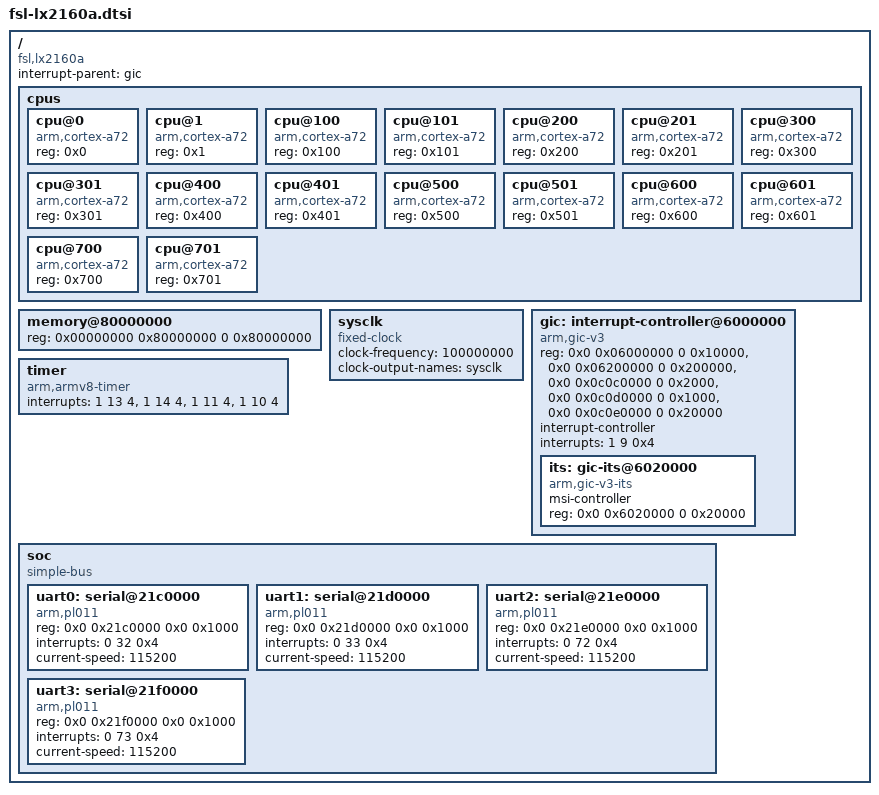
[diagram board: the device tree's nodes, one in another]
/*
 * Device Tree Include file for Layerscape-LX2160A family SoC.
 *
 * Copyright 2017 NXP
 *
 * Sriram Dash <sriram.dash@nxp.com>
 *
 * This file is dual-licensed: you can use it either under the terms
 * of the GPLv2 or the X11 license, at your option. Note that this dual
 * licensing only applies to this file, and not this project as a
 * whole.
 *
 *  a) This library is free software; you can redistribute it and/or
 *     modify it under the terms of the GNU General Public License as
 *     published by the Free Software Foundation; either version 2 of the
 *     License, or (at your option) any later version.
 *
 *     This library is distributed in the hope that it will be useful,
 *     but WITHOUT ANY WARRANTY; without even the implied warranty of
 *     MERCHANTABILITY or FITNESS FOR A PARTICULAR PURPOSE.  See the
 *     GNU General Public License for more details.
 *
 * Or, alternatively,
 *
 *  b) Permission is hereby granted, free of charge, to any person
 *     obtaining a copy of this software and associated documentation
 *     files (the "Software"), to deal in the Software without
 *     restriction, including without limitation the rights to use,
 *     copy, modify, merge, publish, distribute, sublicense, and/or
 *     sell copies of the Software, and to permit persons to whom the
 *     Software is furnished to do so, subject to the following
 *     conditions:
 *
 *     The above copyright notice and this permission notice shall be
 *     included in all copies or substantial portions of the Software.
 *
 *     THE SOFTWARE IS PROVIDED "AS IS", WITHOUT WARRANTY OF ANY KIND,
 *     EXPRESS OR IMPLIED, INCLUDING BUT NOT LIMITED TO THE WARRANTIES
 *     OF MERCHANTABILITY, FITNESS FOR A PARTICULAR PURPOSE AND
 *     NONINFRINGEMENT. IN NO EVENT SHALL THE AUTHORS OR COPYRIGHT
 *     HOLDERS BE LIABLE FOR ANY CLAIM, DAMAGES OR OTHER LIABILITY,
 *     WHETHER IN AN ACTION OF CONTRACT, TORT OR OTHERWISE, ARISING
 *     FROM, OUT OF OR IN CONNECTION WITH THE SOFTWARE OR THE USE OR
 *     OTHER DEALINGS IN THE SOFTWARE.
 */

#include <dt-bindings/interrupt-controller/arm-gic.h>

/memreserve/ 0x80000000 0x00010000;

/ {
	compatible = "fsl,lx2160a";
	interrupt-parent = <&gic>;
	#address-cells = <2>;
	#size-cells = <2>;

	cpus {
		#address-cells = <1>;
		#size-cells = <0>;

		/* We have 8 clusters having 2 Cortex-A72 cores each */
		cpu@0 {
			device_type = "cpu";
			compatible = "arm,cortex-a72";
			reg = <0x0>;
		};

		cpu@1 {
			device_type = "cpu";
			compatible = "arm,cortex-a72";
			reg = <0x1>;
		};

		cpu@100 {
			device_type = "cpu";
			compatible = "arm,cortex-a72";
			reg = <0x100>;
		};

		cpu@101 {
			device_type = "cpu";
			compatible = "arm,cortex-a72";
			reg = <0x101>;
		};

		cpu@200 {
			device_type = "cpu";
			compatible = "arm,cortex-a72";
			reg = <0x200>;
		};

		cpu@201 {
			device_type = "cpu";
			compatible = "arm,cortex-a72";
			reg = <0x201>;
		};

		cpu@300 {
			device_type = "cpu";
			compatible = "arm,cortex-a72";
			reg = <0x300>;
		};

		cpu@301 {
			device_type = "cpu";
			compatible = "arm,cortex-a72";
			reg = <0x301>;
		};

		cpu@400 {
			device_type = "cpu";
			compatible = "arm,cortex-a72";
			reg = <0x400>;
		};

		cpu@401 {
			device_type = "cpu";
			compatible = "arm,cortex-a72";
			reg = <0x401>;
		};

		cpu@500 {
			device_type = "cpu";
			compatible = "arm,cortex-a72";
			reg = <0x500>;
		};

		cpu@501 {
			device_type = "cpu";
			compatible = "arm,cortex-a72";
			reg = <0x501>;
		};

		cpu@600 {
			device_type = "cpu";
			compatible = "arm,cortex-a72";
			reg = <0x600>;
		};

		cpu@601 {
			device_type = "cpu";
			compatible = "arm,cortex-a72";
			reg = <0x601>;
		};

		cpu@700 {
			device_type = "cpu";
			compatible = "arm,cortex-a72";
			reg = <0x700>;
		};

		cpu@701 {
			device_type = "cpu";
			compatible = "arm,cortex-a72";
			reg = <0x701>;
		};

	};

	memory@80000000 {
		device_type = "memory";
		reg = <0x00000000 0x80000000 0 0x80000000>;
		      /* DRAM space - 1, size : 2 GB DRAM */
	};

	sysclk: sysclk {
		compatible = "fixed-clock";
		#clock-cells = <0>;
		clock-frequency = <100000000>;
		clock-output-names = "sysclk";
	};

	gic: interrupt-controller@6000000 {
		compatible = "arm,gic-v3";
		reg = <0x0 0x06000000 0 0x10000>, /* GIC Dist */
		      <0x0 0x06200000 0 0x200000>, /*GICR(RD_base + SGI_base)*/
		      <0x0 0x0c0c0000 0 0x2000>, /* GICC */
		      <0x0 0x0c0d0000 0 0x1000>, /* GICH */
		      <0x0 0x0c0e0000 0 0x20000>; /* GICV */
		#interrupt-cells = <3>;
		#address-cells = <2>;
		#size-cells = <2>;
		ranges;
		interrupt-controller;
		interrupts = <1 9 0x4>;

		its: gic-its@6020000 {
			compatible = "arm,gic-v3-its";
			msi-controller;
			reg = <0x0 0x6020000 0 0x20000>;
		};
	};

	timer {
		compatible = "arm,armv8-timer";
		interrupts = <1 13 4>, /* Physical Secure PPI, active-low */
			     <1 14 4>, /* Physical Non-Secure PPI, active-low */
			     <1 11 4>, /* Virtual PPI, active-low */
			     <1 10 4>; /* Hypervisor PPI, active-low */
	};

	soc {
		compatible = "simple-bus";
		#address-cells = <2>;
		#size-cells = <2>;
		ranges;

		uart0: serial@21c0000 {
			device_type = "serial";
			compatible = "arm,pl011","arm,sbsa-uart";
			reg = <0x0 0x21c0000 0x0 0x1000>;
			interrupts = <0 32 0x4>;
			current-speed = <115200>;
		};

		uart1: serial@21d0000 {
			device_type = "serial";
			compatible = "arm,pl011","arm,sbsa-uart";
			reg = <0x0 0x21d0000 0x0 0x1000>;
			interrupts = <0 33 0x4>;
			current-speed = <115200>;
		};

		uart2: serial@21e0000 {
			device_type = "serial";
			compatible = "arm,pl011","arm,sbsa-uart";
			reg = <0x0 0x21e0000 0x0 0x1000>;
			interrupts = <0 72 0x4>;
			current-speed = <115200>;
		};

		uart3: serial@21f0000 {
			device_type = "serial";
			compatible = "arm,pl011","arm,sbsa-uart";
			reg = <0x0 0x21f0000 0x0 0x1000>;
			interrupts = <0 73 0x4>;
			current-speed = <115200>;
		};
	};
};
